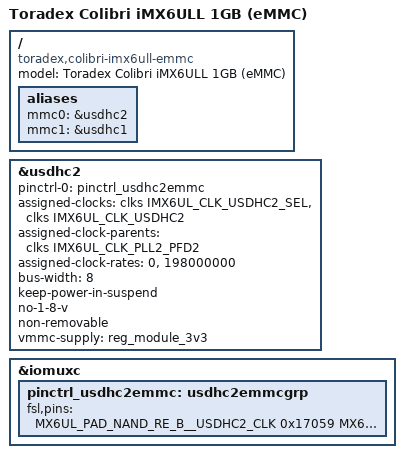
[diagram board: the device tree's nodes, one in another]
// SPDX-License-Identifier: (GPL-2.0+ OR MIT)
/*
 * Copyright 2021 Toradex AG
 */

#include "imx6ull-colibri.dtsi"
#include "imx6ull-colibri-u-boot.dtsi"

/ {
	model = "Toradex Colibri iMX6ULL 1GB (eMMC)";
	compatible = "toradex,colibri-imx6ull-emmc", "toradex,colibri-imx6ull", "fsl,imx6ull";

	aliases {
		mmc0 = &usdhc2;
		mmc1 = &usdhc1;
	};
};

/* eMMC */
&usdhc2 {
	pinctrl-names = "default";
	pinctrl-0 = <&pinctrl_usdhc2emmc>;
	assigned-clocks = <&clks IMX6UL_CLK_USDHC2_SEL>, <&clks IMX6UL_CLK_USDHC2>;
	assigned-clock-parents = <&clks IMX6UL_CLK_PLL2_PFD2>;
	assigned-clock-rates = <0>, <198000000>;
	bus-width = <8>;
	keep-power-in-suspend;
	no-1-8-v;
	non-removable;
	vmmc-supply = <&reg_module_3v3>;
	status = "okay";
};

&iomuxc {
	pinctrl_usdhc2emmc: usdhc2emmcgrp {
		fsl,pins = <
			MX6UL_PAD_NAND_RE_B__USDHC2_CLK     0x17059
			MX6UL_PAD_NAND_WE_B__USDHC2_CMD     0x17059
			MX6UL_PAD_NAND_DATA00__USDHC2_DATA0 0x17059
			MX6UL_PAD_NAND_DATA01__USDHC2_DATA1 0x17059
			MX6UL_PAD_NAND_DATA02__USDHC2_DATA2 0x17059
			MX6UL_PAD_NAND_DATA03__USDHC2_DATA3 0x17059
			MX6UL_PAD_NAND_DATA04__USDHC2_DATA4 0x17059
			MX6UL_PAD_NAND_DATA05__USDHC2_DATA5 0x17059
			MX6UL_PAD_NAND_DATA06__USDHC2_DATA6 0x17059
			MX6UL_PAD_NAND_DATA07__USDHC2_DATA7 0x17059
		>;
	};
};
